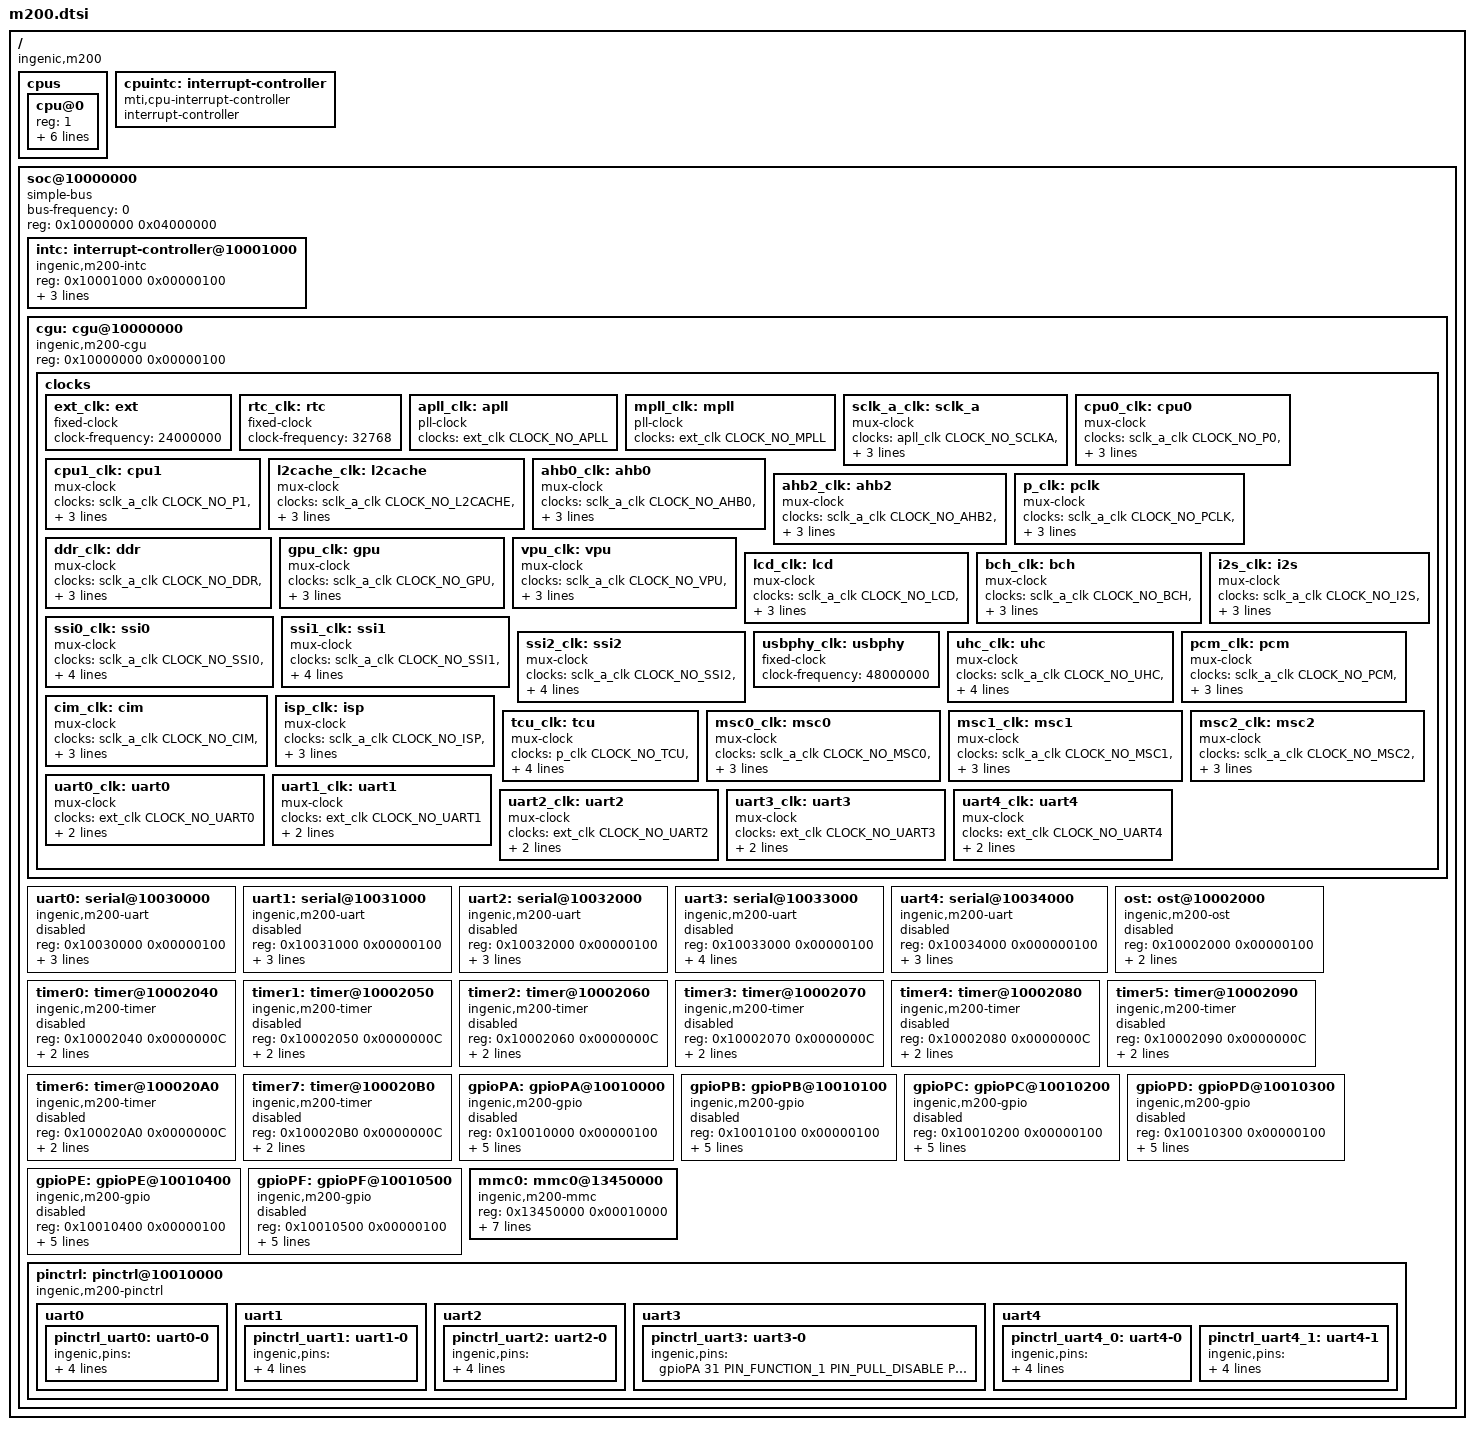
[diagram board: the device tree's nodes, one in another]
/*
 * m200.dtsi - Device Tree Source Interface for M200 SoC
 * Copyright (C) Harvis Wang<jiankangshiye@aliyun.com>
 */
#include "../driverlib/clock.h"
#include "include/dt-bindings/pinctrl/pinctrl.h"

/ {
    #address-cells = <1>;
    #size-cells    = <1>;
    compatible = "ingenic,m200";

    cpus {
        #address-cells = <1>;
        #size-cells    = <0>;

        cpu@0 {
            device_type = "cpu";
            reg = <1>;
            d-cache-line-size = <0x20>;	/* 32 bytes */
            i-cache-line-size = <0x20>;	/* 32 bytes */
            d-cache-size = <0x8000>;	/* L1, 32K */
            i-cache-size = <0x8000>;	/* L1, 32K */
            timebase-frequency = <49500000>;/* 49.5 MHz (csb/4) TBD */
            clock-frequency = <1008000000>;
        };
    };

    cpuintc: interrupt-controller {
        compatible = "mti,cpu-interrupt-controller";
        #address-cells   = <0>;
        #interrupt-cells = <1>;
        interrupt-controller;
    };

    soc@10000000 {
        compatible = "simple-bus";
        #address-cells      = <1>;
        #size-cells         = <1>;
        device_type = "soc";
        ranges = <0x10000000 0xB0000000 0x04000000>;
        bus-frequency = <0>;
        reg = <0x10000000 0x04000000>; /* TODO */

        intc: interrupt-controller@10001000 {
            compatible = "ingenic,m200-intc";
            reg = <0x10001000 0x00000100>;

            interrupt-controller;
            #interrupt-cells = <1>;

            interrupt-parent = <&cpuintc>;
            interrupts = <2>;
        };

        cgu: cgu@10000000 {
            compatible = "ingenic,m200-cgu";
            reg = <0x10000000 0x00000100>;

            clocks {
                ext_clk: ext {
                    compatible = "fixed-clock";
                    #clock-cells = <1>;
                    clock-frequency = <24000000>;
                };

                rtc_clk: rtc {
                    compatible = "fixed-clock";
                    #clock-cells = <1>;
                    clock-frequency = <32768>;
                };

                apll_clk: apll {
                    compatible = "pll-clock";
                    clocks = <&ext_clk CLOCK_NO_APLL>;
                    #clock-cells = <1>;
                };

                mpll_clk: mpll {
                    compatible = "pll-clock";
                    clocks = <&ext_clk CLOCK_NO_MPLL>;
                    #clock-cells = <1>;
                };

                sclk_a_clk: sclk_a {
                    compatible = "mux-clock";
                    clocks = <&apll_clk CLOCK_NO_SCLKA>, <&ext_clk CLOCK_NO_SCLKA>;
                    #clock-cells = <1>;
                    max_divider = <1>;
                    current_parent_index = <0>; /* 0: using apll_clk as parent clock, 1: ext_clk */
                };

                cpu0_clk: cpu0 {
                    compatible = "mux-clock";
                    clocks = <&sclk_a_clk CLOCK_NO_P0>, <&mpll_clk CLOCK_NO_P0>;
                    #clock-cells = <0>;
                    max_divider = <16>;
                    current_parent_index = <0>;
                };

                cpu1_clk: cpu1 {
                    compatible = "mux-clock";
                    clocks = <&sclk_a_clk CLOCK_NO_P1>, <&mpll_clk CLOCK_NO_P1>;
                    #clock-cells = <0>;
                    max_divider = <1>;
                    current_parent_index = <0>;
                };

                l2cache_clk: l2cache {
                    compatible = "mux-clock";
                    clocks = <&sclk_a_clk CLOCK_NO_L2CACHE>, <&mpll_clk CLOCK_NO_L2CACHE>;
                    #clock-cells = <0>;
                    max_divider = <16>;
                    current_parent_index = <0>;
                };

                ahb0_clk: ahb0 {
                    compatible = "mux-clock";
                    clocks = <&sclk_a_clk CLOCK_NO_AHB0>, <&mpll_clk CLOCK_NO_AHB0>;
                    #clock-cells = <0>;
                    max_divider = <16>;
                    current_parent_index = <1>;
                };

                ahb2_clk: ahb2 {
                    compatible = "mux-clock";
                    clocks = <&sclk_a_clk CLOCK_NO_AHB2>, <&mpll_clk CLOCK_NO_AHB2>;
                    #clock-cells = <0>;
                    max_divider = <16>;
                    current_parent_index = <1>;
                };

                p_clk: pclk {
                    compatible = "mux-clock";
                    clocks = <&sclk_a_clk CLOCK_NO_PCLK>, <&mpll_clk CLOCK_NO_PCLK>;
                    #clock-cells = <1>;
                    max_divider = <16>;
                    current_parent_index = <1>; /* should be the same as ahb2_clk, as they are controlled together */
                };

                ddr_clk: ddr {
                    compatible = "mux-clock";
                    clocks = <&sclk_a_clk CLOCK_NO_DDR>, <&mpll_clk CLOCK_NO_DDR>;
                    #clock-cells = <0>;
                    max_divider = <16>;
                    current_parent_index = <1>;
                };

                gpu_clk: gpu {
                    compatible = "mux-clock";
                    clocks = <&sclk_a_clk CLOCK_NO_GPU>, <&mpll_clk CLOCK_NO_GPU>;
                    #clock-cells = <0>;
                    max_divider = <16>;
                    current_parent_index = <1>;
                };

                vpu_clk: vpu {
                    compatible = "mux-clock";
                    clocks = <&sclk_a_clk CLOCK_NO_VPU>, <&mpll_clk CLOCK_NO_VPU>;
                    #clock-cells = <0>;
                    max_divider = <16>;
                    current_parent_index = <1>;
                };

                lcd_clk: lcd {
                    compatible = "mux-clock";
                    clocks = <&sclk_a_clk CLOCK_NO_LCD>, <&mpll_clk CLOCK_NO_LCD>;
                    #clock-cells = <0>;
                    max_divider = <256>;
                    current_parent_index = <1>;
                };

                bch_clk: bch {
                    compatible = "mux-clock";
                    clocks = <&sclk_a_clk CLOCK_NO_BCH>, <&mpll_clk CLOCK_NO_BCH>;
                    #clock-cells = <0>;
                    max_divider = <16>;
                    current_parent_index = <1>;
                };

                i2s_clk: i2s {
                    compatible = "mux-clock";
                    clocks = <&sclk_a_clk CLOCK_NO_I2S>, <&mpll_clk CLOCK_NO_I2S>, <&ext_clk CLOCK_NO_I2S>;
                    #clock-cells = <0>;
                    max_divider = <256>;
                    current_parent_index = <2>;
                };

                ssi0_clk: ssi0 {
                    compatible = "mux-clock";
                    clocks = <&sclk_a_clk CLOCK_NO_SSI0>, <&mpll_clk CLOCK_NO_SSI0>, <&ext_clk CLOCK_NO_SSI0>;
                    #clock-cells = <0>;
                    max_divider = <256>;
                    current_parent_index = <2>;
                };

                ssi1_clk: ssi1 {
                    compatible = "mux-clock";
                    clocks = <&sclk_a_clk CLOCK_NO_SSI1>, <&mpll_clk CLOCK_NO_SSI1>, <&ext_clk CLOCK_NO_SSI1>;
                    #clock-cells = <0>;
                    max_divider = <256>;
                    current_parent_index = <2>;
                };

                ssi2_clk: ssi2 {
                    compatible = "mux-clock";
                    clocks = <&sclk_a_clk CLOCK_NO_SSI2>, <&mpll_clk CLOCK_NO_SSI2>, <&ext_clk CLOCK_NO_SSI2>;
                    #clock-cells = <0>;
                    max_divider = <256>;
                    current_parent_index = <2>;
                };

                usbphy_clk: usbphy { /* TODO */
                    compatible = "fixed-clock";
                    #clock-cells = <1>;
                    clock-frequency = <48000000>;
                };

                uhc_clk: uhc {
                    compatible = "mux-clock";
                    clocks = <&sclk_a_clk CLOCK_NO_UHC>, <&mpll_clk CLOCK_NO_UHC>, <&usbphy_clk CLOCK_NO_UHC>;
                    #clock-cells = <0>;
                    max_divider = <256>;
                    current_parent_index = <1>;
                };

                pcm_clk: pcm {
                    compatible = "mux-clock";
                    clocks = <&sclk_a_clk CLOCK_NO_PCM>, <&mpll_clk CLOCK_NO_PCM>, <&ext_clk CLOCK_NO_PCM>;
                    #clock-cells = <0>;
                    max_divider = <256>;
                    current_parent_index = <2>;
                };

                cim_clk: cim {
                    compatible = "mux-clock";
                    clocks = <&sclk_a_clk CLOCK_NO_CIM>, <&mpll_clk CLOCK_NO_CIM>;
                    #clock-cells = <0>;
                    max_divider = <256>;
                    current_parent_index = <1>;
                };

                isp_clk: isp {
                    compatible = "mux-clock";
                    clocks = <&sclk_a_clk CLOCK_NO_ISP>, <&mpll_clk CLOCK_NO_ISP>;
                    #clock-cells = <0>;
                    max_divider = <16>;
                    current_parent_index = <1>;
                };

                tcu_clk: tcu {
                    compatible = "mux-clock";
                    clocks = <&p_clk CLOCK_NO_TCU>, <&rtc_clk CLOCK_NO_TCU>, <&ext_clk CLOCK_NO_TCUEXCLK>;
                    #clock-cells = <0>;
                    max_divider = <1>;
                    current_parent_index = <2>;
                };

                msc0_clk: msc0 {
                    compatible = "mux-clock";
                    clocks = <&sclk_a_clk CLOCK_NO_MSC0>, <&mpll_clk CLOCK_NO_MSC0>;
                    #clock-cells = <0>;
                    max_divider = <512>;
                    current_parent_index = <1>;
                };

                msc1_clk: msc1 {
                    compatible = "mux-clock";
                    clocks = <&sclk_a_clk CLOCK_NO_MSC1>, <&mpll_clk CLOCK_NO_MSC1>;
                    #clock-cells = <0>;
                    max_divider = <512>;
                    current_parent_index = <1>;
                };

                msc2_clk: msc2 {
                    compatible = "mux-clock";
                    clocks = <&sclk_a_clk CLOCK_NO_MSC2>, <&mpll_clk CLOCK_NO_MSC2>;
                    #clock-cells = <0>;
                    max_divider = <512>;
                    current_parent_index = <1>;
                };

                uart0_clk: uart0 {
                    compatible = "mux-clock";
                    clocks = <&ext_clk CLOCK_NO_UART0>;
                    #clock-cells = <0>;
                    max_divider = <1>;
                    current_parent_index = <0>;
                };

                uart1_clk: uart1 {
                    compatible = "mux-clock";
                    clocks = <&ext_clk CLOCK_NO_UART1>;
                    #clock-cells = <0>;
                    max_divider = <1>;
                    current_parent_index = <0>;
                };

                uart2_clk: uart2 {
                    compatible = "mux-clock";
                    clocks = <&ext_clk CLOCK_NO_UART2>;
                    #clock-cells = <0>;
                    max_divider = <1>;
                    current_parent_index = <0>;
                };

                uart3_clk: uart3 {
                    compatible = "mux-clock";
                    clocks = <&ext_clk CLOCK_NO_UART3>;
                    #clock-cells = <0>;
                    max_divider = <1>;
                    current_parent_index = <0>;
                };

                uart4_clk: uart4 {
                    compatible = "mux-clock";
                    clocks = <&ext_clk CLOCK_NO_UART4>;
                    #clock-cells = <0>;
                    max_divider = <1>;
                    current_parent_index = <0>;
                };
            };
        };

        uart0: serial@10030000 {
            compatible = "ingenic,m200-uart";
            reg = <0x10030000 0x00000100>;

            interrupt-parent = <&intc>;
            interrupts = <51>;

            clocks = <&uart0_clk>;

            status = "disabled";
        };

        uart1: serial@10031000 {
            compatible = "ingenic,m200-uart";
            reg = <0x10031000 0x00000100>;

            interrupt-parent = <&intc>;
            interrupts = <50>;

            clocks = <&uart1_clk>;

            status = "disabled";
        };

        uart2: serial@10032000 {
            compatible = "ingenic,m200-uart";
            reg = <0x10032000 0x00000100>;

            interrupt-parent = <&intc>;
            interrupts = <49>;

            clocks = <&uart2_clk>;

            status = "disabled";
        };

        uart3: serial@10033000 {
            compatible = "ingenic,m200-uart";
            reg = <0x10033000 0x00000100>;

            interrupt-parent = <&intc>;
            interrupts = <48>;

            clocks = <&uart3_clk>;
            pinctrl-names = "default";
            pinctrl-0 = <&pinctrl_uart3>;

            status = "disabled";
        };

        uart4: serial@10034000 {
            compatible = "ingenic,m200-uart";
            reg = <0x10034000 0x000000100>;

            interrupt-parent = <&intc>;
            interrupts = <34>;

            clocks = <&uart4_clk>;

            status = "disabled";
        };

        ost: ost@10002000 {
            compatible = "ingenic,m200-ost";
            reg = <0x10002000 0x00000100>;

            interrupt-parent = <&intc>;
            interrupts = <27>;

            status = "disabled";
        };

        timer0: timer@10002040 {
            compatible = "ingenic,m200-timer";
            reg = <0x10002040 0x0000000C>;

            interrupt-parent = <&intc>;
            interrupts = <25>;

            status = "disabled";
        };

        timer1: timer@10002050 {
            compatible = "ingenic,m200-timer";
            reg = <0x10002050 0x0000000C>;

            interrupt-parent = <&intc>;
            interrupts = <25>;

            status = "disabled";
        };

        timer2: timer@10002060 {
            compatible = "ingenic,m200-timer";
            reg = <0x10002060 0x0000000C>;

            interrupt-parent = <&intc>;
            interrupts = <25>;

            status = "disabled";
        };

        timer3: timer@10002070 {
            compatible = "ingenic,m200-timer";
            reg = <0x10002070 0x0000000C>;

            interrupt-parent = <&intc>;
            interrupts = <25>;

            status = "disabled";
        };

        timer4: timer@10002080 {
            compatible = "ingenic,m200-timer";
            reg = <0x10002080 0x0000000C>;

            interrupt-parent = <&intc>;
            interrupts = <25>;

            status = "disabled";
        };

        timer5: timer@10002090 {
            compatible = "ingenic,m200-timer";
            reg = <0x10002090 0x0000000C>;

            interrupt-parent = <&intc>;
            interrupts = <26>;

            status = "disabled";
        };

        timer6: timer@100020A0 {
            compatible = "ingenic,m200-timer";
            reg = <0x100020A0 0x0000000C>;

            interrupt-parent = <&intc>;
            interrupts = <25>;

            status = "disabled";
        };

        timer7: timer@100020B0 {
            compatible = "ingenic,m200-timer";
            reg = <0x100020B0 0x0000000C>;

            interrupt-parent = <&intc>;
            interrupts = <25>;

            status = "disabled";
        };

        gpioPA: gpioPA@10010000 {
            compatible = "ingenic,m200-gpio";
            reg = <0x10010000 0x00000100>;

            interrupt-controller;
            #interrupt-cells = <2>; /* cell[0] hwirq, cell[1] irq type
                                     * cell[1] note:
                                     * 0: IRQ_TYPE_NONE
                                     * 1: IRQ_TYPE_EDGE_RISING
                                     * 2: IRQ_TYPE_EDGE_FALLING
                                     * 3: IRQ_TYPE_EDGE_BOTH
                                     * 4: IRQ_TYPE_LEVEL_HIGH
                                     * 8: IRQ_TYPE_LEVEL_LOW
                                     */

            interrupt-parent = <&intc>;
            interrupts = <17>;

            gpio-controller;
            #gpio-cells = <2>;
            ngpios = <32>;

            #pinctrl-cells = <5>;
            status = "disabled";
        };

        gpioPB: gpioPB@10010100 {
            compatible = "ingenic,m200-gpio";
            reg = <0x10010100 0x00000100>;

            interrupt-controller;
            #interrupt-cells = <2>;

            interrupt-parent = <&intc>;
            interrupts = <16>;

            gpio-controller;
            #gpio-cells = <2>;
            ngpios = <32>;

            #pinctrl-cells = <5>;
            status = "disabled";
        };

        gpioPC: gpioPC@10010200 {
            compatible = "ingenic,m200-gpio";
            reg = <0x10010200 0x00000100>;

            interrupt-controller;
            #interrupt-cells = <2>;

            interrupt-parent = <&intc>;
            interrupts = <15>;

            gpio-controller;
            #gpio-cells = <2>;
            ngpios = <32>;

            #pinctrl-cells = <5>;
            status = "disabled";
        };

        gpioPD: gpioPD@10010300 {
            compatible = "ingenic,m200-gpio";
            reg = <0x10010300 0x00000100>;

            interrupt-controller;
            #interrupt-cells = <2>;

            interrupt-parent = <&intc>;
            interrupts = <14>;

            gpio-controller;
            #gpio-cells = <2>;
            ngpios = <32>;

            #pinctrl-cells = <5>;
            status = "disabled";
        };

        gpioPE: gpioPE@10010400 {
            compatible = "ingenic,m200-gpio";
            reg = <0x10010400 0x00000100>;

            interrupt-controller;
            #interrupt-cells = <2>;

            interrupt-parent = <&intc>;
            interrupts = <13>;

            gpio-controller;
            #gpio-cells = <2>;
            ngpios = <32>;

            #pinctrl-cells = <5>;
            status = "disabled";
        };

        gpioPF: gpioPF@10010500 {
            compatible = "ingenic,m200-gpio";
            reg = <0x10010500 0x00000100>;

            interrupt-controller;
            #interrupt-cells = <2>;

            interrupt-parent = <&intc>;
            interrupts = <12>;

            gpio-controller;
            #gpio-cells = <2>;
            ngpios = <32>;

            #pinctrl-cells = <5>;
            status = "disabled";
        };

        mmc0: mmc0@13450000 {
            compatible = "ingenic,m200-mmc";
            reg = <0x13450000 0x00010000>;

            min-frequency = <20000000>;
            max-frequency = <50000000>;
            bus-width = <8>;
            sdma-descriptor-count = <8>;

            interrupt-parent = <&intc>;
            interrupts = <37>;

            clocks = <&msc0_clk>;
        };

        pinctrl: pinctrl@10010000 {
            compatible = "ingenic,m200-pinctrl";

            uart0 {
                pinctrl_uart0: uart0-0 {
                    ingenic,pins = <&gpioPF 0 PIN_FUNCTION_2 PIN_PULL_DISABLE PIN_SLEEP_FUNCTION_1 PIN_SLEEP_PULL_DISABLE>,
                                   <&gpioPF 1 PIN_FUNCTION_2 PIN_PULL_DISABLE PIN_SLEEP_FUNCTION_1 PIN_SLEEP_PULL_DISABLE>,
                                   <&gpioPF 2 PIN_FUNCTION_2 PIN_PULL_DISABLE PIN_SLEEP_FUNCTION_1 PIN_SLEEP_PULL_DISABLE>,
                                   <&gpioPF 3 PIN_FUNCTION_2 PIN_PULL_DISABLE PIN_SLEEP_FUNCTION_1 PIN_SLEEP_PULL_DISABLE>;
                };
            };

            uart1 {
                pinctrl_uart1: uart1-0 {
                    ingenic,pins = <&gpioPD 26 PIN_FUNCTION_2 PIN_PULL_DISABLE PIN_SLEEP_FUNCTION_1 PIN_SLEEP_PULL_DISABLE>,
                                   <&gpioPD 27 PIN_FUNCTION_2 PIN_PULL_DISABLE PIN_SLEEP_FUNCTION_1 PIN_SLEEP_PULL_DISABLE>,
                                   <&gpioPD 28 PIN_FUNCTION_2 PIN_PULL_DISABLE PIN_SLEEP_FUNCTION_1 PIN_SLEEP_PULL_DISABLE>,
                                   <&gpioPD 29 PIN_FUNCTION_2 PIN_PULL_DISABLE PIN_SLEEP_FUNCTION_1 PIN_SLEEP_PULL_DISABLE>;
                };
            };

            uart2 {
                pinctrl_uart2: uart2-0 {
                    ingenic,pins = <&gpioPF 6 PIN_FUNCTION_2 PIN_PULL_DISABLE PIN_SLEEP_FUNCTION_1 PIN_SLEEP_PULL_DISABLE>,
                                   <&gpioPF 7 PIN_FUNCTION_2 PIN_PULL_DISABLE PIN_SLEEP_FUNCTION_1 PIN_SLEEP_PULL_DISABLE>,
                                   <&gpioPC 10 PIN_FUNCTION_2 PIN_PULL_DISABLE PIN_SLEEP_FUNCTION_1 PIN_SLEEP_PULL_DISABLE>,
                                   <&gpioPC 20 PIN_FUNCTION_2 PIN_PULL_DISABLE PIN_SLEEP_FUNCTION_1 PIN_SLEEP_PULL_DISABLE>;
                };
            };

            uart3 {
                pinctrl_uart3: uart3-0 {
                    ingenic,pins = <&gpioPA 31 PIN_FUNCTION_1 PIN_PULL_DISABLE PIN_SLEEP_FUNCTION_1 PIN_SLEEP_PULL_DISABLE>;
                };
            };

            uart4 {
                pinctrl_uart4_0: uart4-0 {
                    ingenic,pins = <&gpioPB 2 PIN_FUNCTION_2 PIN_PULL_DISABLE PIN_SLEEP_FUNCTION_1 PIN_SLEEP_PULL_DISABLE>,
                                   <&gpioPB 3 PIN_FUNCTION_2 PIN_PULL_DISABLE PIN_SLEEP_FUNCTION_1 PIN_SLEEP_PULL_DISABLE>,
                                   <&gpioPB 4 PIN_FUNCTION_2 PIN_PULL_DISABLE PIN_SLEEP_FUNCTION_1 PIN_SLEEP_PULL_DISABLE>,
                                   <&gpioPB 5 PIN_FUNCTION_2 PIN_PULL_DISABLE PIN_SLEEP_FUNCTION_1 PIN_SLEEP_PULL_DISABLE>;
                };

                pinctrl_uart4_1: uart4-1 {
                    ingenic,pins = <&gpioPB 20 PIN_FUNCTION_2 PIN_PULL_DISABLE PIN_SLEEP_FUNCTION_1 PIN_SLEEP_PULL_DISABLE>,
                                   <&gpioPB 21 PIN_FUNCTION_2 PIN_PULL_DISABLE PIN_SLEEP_FUNCTION_1 PIN_SLEEP_PULL_DISABLE>,
                                   <&gpioPB 28 PIN_FUNCTION_2 PIN_PULL_DISABLE PIN_SLEEP_FUNCTION_1 PIN_SLEEP_PULL_DISABLE>,
                                   <&gpioPB 29 PIN_FUNCTION_2 PIN_PULL_DISABLE PIN_SLEEP_FUNCTION_1 PIN_SLEEP_PULL_DISABLE>;
                };

                //pinctrl_uart4_2: uart4-2 {
                //    ingenic,pins = <&gpioPF 1 PIN_FUNCTION_1 PIN_PULL_DISABLE PIN_SLEEP_FUNCTION_1 PIN_SLEEP_PULL_DISABLE>,
                //                   <&gpioPF 2 PIN_FUNCTION_1 PIN_PULL_DISABLE PIN_SLEEP_FUNCTION_1 PIN_SLEEP_PULL_DISABLE>;
                //};
            };
        };
    };
};
